# nrf5340_application register map
Vendor: Nordic Semiconductor; Series: nrf53; File version: 1
CPU: CM33 r0p4, little endian, MPU, FPU, 3 interrupt priority bits, 69 interrupts
Registers are 32-bit, read-write, reset 0x0 unless marked. A register's access mark holds for its fields unless they carry their own. Offsets are from the block's base; [hi:lo] are bit positions; lines under a group give offsets from that group; {n}, {i} and the like mark numbered series.

## UICR_S — User Information Configuration Registers User information configuration registers
Base 0x00FF8000
0x00 APPROTECT — Access port protection
  [31:0] PALL — Blocks debugger read/write access to all CPU registers and memory mapped addresses Using any value not listed below will yield unexpected results.
    0xFFFFFFFF=Unprotected; 0=Protected
0x0C EXTSUPPLY reset 0xFFFFFFFF — Enable external circuitry to be supplied from VDD pin. Applicable in 'High voltage mode' only.
  [0] EXTSUPPLY — Enable external circuitry to be supplied from VDD pin (output of VREGH stage).
    1=Disabled (No current can be drawn from the VDD pin.); 0=Enabled (It is allowed to supply external circuitry from the VDD pin.)
0x10 VREGHVOUT reset 0xFFFFFFFF — GPIO reference voltage / external output supply voltage in 'High voltage mode'.
  [2:0] VREGHVOUT — VREGH regulator output voltage. The maximum output voltage from this stage is given as VDDH - VEXDIF.
    0=1V8 (1.8 V); 1=2V1 (2.1 V); 2=2V4 (2.4 V); 3=2V7 (2.7 V); 4=3V0 (3.0 V); 5=3V3 (3.3 V); 7=DEFAULT (Default voltage: 1.8 V)
0x14 HFXOCNT reset 0xFFFFFFFF — HFXO startup counter
  [7:0] HFXOCNT — HFXO startup counter. Total debounce time = HFXOCNT*64 us + 0.5 us
    0=Min debounce time = (0*64 us + 0.5 us); 254=Max debounce time = (254*64 us + 0.5 us); 255=Default debounce time for erased UICR = 4*64 us + 0.5 us
0x1C SECUREAPPROTECT — Secure access port protection
  [31:0] PALL — Blocks debugger read/write access to all secure CPU registers and secure memory mapped addresses. Using any value not listed below will yield unexpected results.
    0xFFFFFFFF=Unprotected; 0=Protected
0x20 ERASEPROTECT — Erase protection
  [31:0] PALL — Blocks NVMC ERASEALL and CTRLAP ERASEALL functionality. Using any value not listed below will yield unexpected results.
    0xFFFFFFFF=Unprotected; 0=Protected
0x24 TINSTANCE reset 0xFFFFFFFF — SW-DP Target instance
  [31:28] TINSTANCE — TINSTANCE bits are negated and used in the SW-DP DLPIDR.TINSTANCE field. E.g. 0xF in this field is translated to 0x0 in DLPIDR.TINSTANCE field.
0x28 NFCPINS reset 0xFFFFFFFF — Setting of pins dedicated to NFC functionality: NFC antenna or GPIO
  [0] PROTECT — Setting of pins dedicated to NFC functionality
    0=Disabled (Operation as GPIO pins. Same protection as normal GPIO pins); 1=NFC (Operation as NFC antenna pins. Configures the protection for NFC operation)
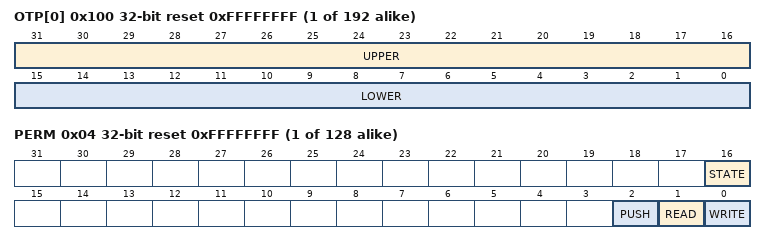
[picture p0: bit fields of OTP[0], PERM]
{0x100+4i} OTP[{i}] (i=0..191) reset 0xFFFFFFFF — Description collection: One time programmable memory
  [31:16] UPPER rw-once — Upper half word
  [15:0] LOWER rw-once — Lower half word
0x400 KEYSLOT group — Unspecified
  {0x0+8j} CONFIG[{j}] (j=0..127) group — Unspecified
    0x00 DEST reset 0xFFFFFFFF — Description cluster: Destination address where content of the key value registers (KEYSLOT.KEYn.VALUE[0-3]) will be pushed by KMU. Note that this address must match that of a peripherals APB mapped write-only key registers, else the KMU can push this key value into an address range which the CPU can potentially read.
      [31:0] DEST — Secure APB destination address
    0x04 PERM reset 0xFFFFFFFF — Description cluster: Define permissions for the key slot. Bits 0-15 and 16-31 can only be written when equal to 0xFFFF.
      [16] STATE — Revocation state for the key slot
        0=Revoked (Key value registers can no longer be read or pushed); 1=Active (Key value registers are readable (if enabled) and can be pushed (if enabled))
      [2] PUSH — Push permission for key slot
        0=Disabled (Disable pushing of key value registers over secure APB, but can be read if field READ is Enabled); 1=Enabled (Enable pushing of key value registers over secure APB. Register KEYSLOT.CONFIGn.DEST must contain a valid destination address!)
      [1] READ — Read permission for key slot
        0=Disabled (Disable read from key value registers); 1=Enabled (Enable read from key value registers)
      [0] WRITE — Write permission for key slot
        0=Disabled (Disable write to the key value registers); 1=Enabled (Enable write to the key value registers)
  {0x400+0x10*j} KEY[{j}] (j=0..127) group — Unspecified
    {0x0+4k} VALUE[{k}] (k=0..3) reset 0xFFFFFFFF — Description collection: Define bits [31+o*32:0+o*32] of value assigned to KMU key slot.
      [31:0] VALUE — Define bits [31+o*32:0+o*32] of value assigned to KMU key slot

## Notices in the file
Copyright (c) 2010 - 2020, Nordic Semiconductor ASA All rights reserved.
Redistribution and use in source and binary forms, with or without
modification, are permitted provided that the following conditions are met:
1. Redistributions of source code must retain the above copyright notice, this
list of conditions and the following disclaimer.
2. Redistributions in binary form must reproduce the above copyright
notice, this list of conditions and the following disclaimer in the
documentation and/or other materials provided with the distribution.
3. Neither the name of Nordic Semiconductor ASA nor the names of its
contributors may be used to endorse or promote products derived from this
software without specific prior written permission.
THIS SOFTWARE IS PROVIDED BY THE COPYRIGHT HOLDERS AND CONTRIBUTORS "AS IS"
AND ANY EXPRESS OR IMPLIED WARRANTIES, INCLUDING, BUT NOT LIMITED TO, THE
IMPLIED WARRANTIES OF MERCHANTABILITY, AND FITNESS FOR A PARTICULAR PURPOSE
ARE DISCLAIMED. IN NO EVENT SHALL NORDIC SEMICONDUCTOR ASA OR CONTRIBUTORS BE
LIABLE FOR ANY DIRECT, INDIRECT, INCIDENTAL, SPECIAL, EXEMPLARY, OR
CONSEQUENTIAL DAMAGES (INCLUDING, BUT NOT LIMITED TO, PROCUREMENT OF
SUBSTITUTE GOODS OR SERVICES; LOSS OF USE, DATA, OR PROFITS; OR BUSINESS
INTERRUPTION) HOWEVER CAUSED AND ON ANY THEORY OF LIABILITY, WHETHER IN
CONTRACT, STRICT LIABILITY, OR TORT (INCLUDING NEGLIGENCE OR OTHERWISE)
ARISING IN ANY WAY OUT OF THE USE OF THIS SOFTWARE, EVEN IF ADVISED OF THE
POSSIBILITY OF SUCH DAMAGE.
